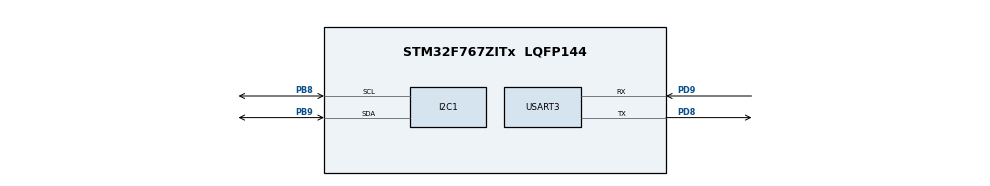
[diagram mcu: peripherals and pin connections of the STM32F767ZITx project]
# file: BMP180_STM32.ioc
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CORTEX_M7.default_mode_Activation=1
Mcu.Family=STM32F7
Mcu.Name=STM32F767ZITx
Mcu.Package=LQFP144
NVIC.PriorityGroup=NVIC_PRIORITYGROUP_4
PB8.Mode=I2C
PB8.Signal=I2C1_SCL
PB9.Mode=I2C
PB9.Signal=I2C1_SDA
PD8.Mode=Asynchronous
PD8.Signal=USART3_TX
PD9.Mode=Asynchronous
PD9.Signal=USART3_RX
ProjectManager.HeapSize=0x200
ProjectManager.StackSize=0x400
ProjectManager.TargetToolchain=STM32CubeIDE
RCC.HSE_VALUE=25000000
RCC.HSI_VALUE=16000000
RCC.LSE_VALUE=32768
RCC.USBFreq_Value=96000000
RCC.VCOOutputFreq_Value=192000000
USART3.VirtualMode-Asynchronous=VM_ASYNC
board=custom

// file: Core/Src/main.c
/* USER CODE BEGIN Header */
/**
  ******************************************************************************
  * @file           : main.c
  * @brief          : Main program body
  ******************************************************************************
  * @attention
  *
  * Copyright (c) 2026 STMicroelectronics.
  * All rights reserved.
  *
  * This software is licensed under terms that can be found in the LICENSE file
  * in the root directory of this software component.
  * If no LICENSE file comes with this software, it is provided AS-IS.
  *
  ******************************************************************************
  */
/* USER CODE END Header */
#include "main.h"
#include "i2c.h"
#include "usart.h"
#include "gpio.h"

/* USER CODE BEGIN Includes */
#include "stdio.h"

#include "BMP180.h"

/* USER CODE END Includes */

/* USER CODE BEGIN PV */
float pressure, temperature;
/* USER CODE END PV */

void SystemClock_Config(void);
static void MPU_Config(void);

int main(void)
{

  /* MPU Configuration--------------------------------------------------------*/
  MPU_Config();

  /* MCU Configuration--------------------------------------------------------*/

  /* Reset of all peripherals, Initializes the Flash interface and the Systick. */
  HAL_Init();

  /* Configure the system clock */
  SystemClock_Config();

  /* Initialize all configured peripherals */
  MX_GPIO_Init();
  MX_I2C1_Init();
  MX_USART3_UART_Init();
  /* USER CODE BEGIN 2 */
  BMP180_init();

  /* USER CODE END 2 */

  /* Infinite loop */
  while (1)
  {

    /* USER CODE BEGIN 3 */
	  update_BMP180(OSS3);
	  temperature=get_temperature();
	  pressure=get_pressure();

	  printf("Temperature = %0.4f and Pressure =%0.4f\r\n",temperature,pressure);

	  HAL_Delay(200);

  }
  /* USER CODE END 3 */
}

void SystemClock_Config(void)
{
  RCC_OscInitTypeDef RCC_OscInitStruct = {0};
  RCC_ClkInitTypeDef RCC_ClkInitStruct = {0};

  /** Configure the main internal regulator output voltage
  */
  __HAL_RCC_PWR_CLK_ENABLE();
  __HAL_PWR_VOLTAGESCALING_CONFIG(PWR_REGULATOR_VOLTAGE_SCALE3);

  /** Initializes the RCC Oscillators according to the specified parameters
  * in the RCC_OscInitTypeDef structure.
  */
  RCC_OscInitStruct.OscillatorType = RCC_OSCILLATORTYPE_HSI;
  RCC_OscInitStruct.HSIState = RCC_HSI_ON;
  RCC_OscInitStruct.HSICalibrationValue = RCC_HSICALIBRATION_DEFAULT;
  RCC_OscInitStruct.PLL.PLLState = RCC_PLL_NONE;
  if (HAL_RCC_OscConfig(&RCC_OscInitStruct) != HAL_OK)
  {
    Error_Handler();
  }

  /** Initializes the CPU, AHB and APB buses clocks
  */
  RCC_ClkInitStruct.ClockType = RCC_CLOCKTYPE_HCLK|RCC_CLOCKTYPE_SYSCLK
                              |RCC_CLOCKTYPE_PCLK1|RCC_CLOCKTYPE_PCLK2;
  RCC_ClkInitStruct.SYSCLKSource = RCC_SYSCLKSOURCE_HSI;
  RCC_ClkInitStruct.AHBCLKDivider = RCC_SYSCLK_DIV1;
  RCC_ClkInitStruct.APB1CLKDivider = RCC_HCLK_DIV1;
  RCC_ClkInitStruct.APB2CLKDivider = RCC_HCLK_DIV1;

  if (HAL_RCC_ClockConfig(&RCC_ClkInitStruct, FLASH_LATENCY_0) != HAL_OK)
  {
    Error_Handler();
  }
}

 /* MPU Configuration */

void MPU_Config(void)
{
  MPU_Region_InitTypeDef MPU_InitStruct = {0};

  /* Disables the MPU */
  HAL_MPU_Disable();

  /** Initializes and configures the Region and the memory to be protected
  */
  MPU_InitStruct.Enable = MPU_REGION_ENABLE;
  MPU_InitStruct.Number = MPU_REGION_NUMBER0;
  MPU_InitStruct.BaseAddress = 0x0;
  MPU_InitStruct.Size = MPU_REGION_SIZE_4GB;
  MPU_InitStruct.SubRegionDisable = 0x87;
  MPU_InitStruct.TypeExtField = MPU_TEX_LEVEL0;
  MPU_InitStruct.AccessPermission = MPU_REGION_NO_ACCESS;
  MPU_InitStruct.DisableExec = MPU_INSTRUCTION_ACCESS_DISABLE;
  MPU_InitStruct.IsShareable = MPU_ACCESS_SHAREABLE;
  MPU_InitStruct.IsCacheable = MPU_ACCESS_NOT_CACHEABLE;
  MPU_InitStruct.IsBufferable = MPU_ACCESS_NOT_BUFFERABLE;

  HAL_MPU_ConfigRegion(&MPU_InitStruct);
  /* Enables the MPU */
  HAL_MPU_Enable(MPU_PRIVILEGED_DEFAULT);

}

void Error_Handler(void)
{
  __disable_irq();
  while (1)
  {
  }
}
